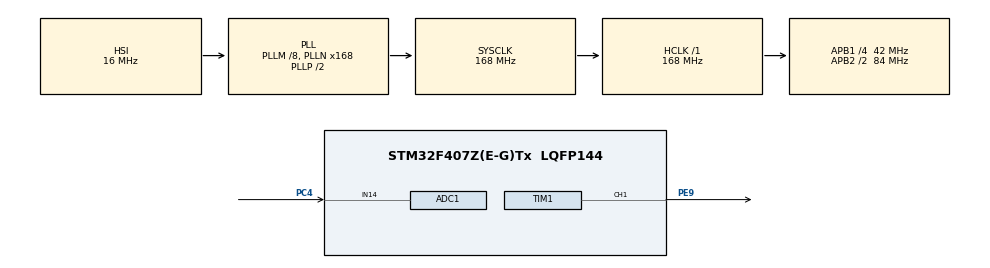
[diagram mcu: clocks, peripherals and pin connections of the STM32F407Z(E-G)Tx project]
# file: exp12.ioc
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ADC1.Channel-0\#ChannelRegularConversion=ADC_CHANNEL_14
ADC1.ContinuousConvMode=ENABLE
ADC1.DMAContinuousRequests=ENABLE
ADC1.NbrOfConversionFlag=1
ADC1.Rank-0\#ChannelRegularConversion=1
ADC1.SamplingTime-0\#ChannelRegularConversion=ADC_SAMPLETIME_3CYCLES
ADC1.master=1
Dma.ADC1.0.Direction=DMA_PERIPH_TO_MEMORY
Dma.ADC1.0.FIFOMode=DMA_FIFOMODE_DISABLE
Dma.ADC1.0.Instance=DMA2_Stream0
Dma.ADC1.0.MemDataAlignment=DMA_MDATAALIGN_HALFWORD
Dma.ADC1.0.MemInc=DMA_MINC_ENABLE
Dma.ADC1.0.Mode=DMA_CIRCULAR
Dma.ADC1.0.PeriphDataAlignment=DMA_PDATAALIGN_HALFWORD
Dma.ADC1.0.PeriphInc=DMA_PINC_DISABLE
Dma.ADC1.0.Priority=DMA_PRIORITY_LOW
Dma.Request0=ADC1
Mcu.Family=STM32F4
Mcu.Name=STM32F407Z(E-G)Tx
Mcu.Package=LQFP144
NVIC.DMA2_Stream0_IRQn=true\:0\:0\:false\:false\:true\:false\:true
NVIC.PriorityGroup=NVIC_PRIORITYGROUP_4
PC14-OSC32_IN.Mode=LSE-External-Oscillator
PC14-OSC32_IN.Signal=RCC_OSC32_IN
PC15-OSC32_OUT.Mode=LSE-External-Oscillator
PC15-OSC32_OUT.Signal=RCC_OSC32_OUT
PC4.Signal=ADCx_IN14
PE9.Signal=S_TIM1_CH1
ProjectManager.HeapSize=0x200
ProjectManager.StackSize=0x400
ProjectManager.TargetToolchain=MDK-ARM V5.27
RCC.48MHZClocksFreq_Value=84000000
RCC.AHBFreq_Value=168000000
RCC.APB1CLKDivider=RCC_HCLK_DIV4
RCC.APB1Freq_Value=42000000
RCC.APB1TimFreq_Value=84000000
RCC.APB2CLKDivider=RCC_HCLK_DIV2
RCC.APB2Freq_Value=84000000
RCC.APB2TimFreq_Value=168000000
RCC.CortexFreq_Value=168000000
RCC.HCLKFreq_Value=168000000
RCC.HSE_VALUE=25000000
RCC.HSI_VALUE=16000000
RCC.PLLM=8
RCC.PLLN=168
RCC.SYSCLKFreq_VALUE=168000000
RCC.SYSCLKSource=RCC_SYSCLKSOURCE_PLLCLK
RCC.VCOOutputFreq_Value=336000000
SH.ADCx_IN14.0=ADC1_IN14,IN14
SH.S_TIM1_CH1.0=TIM1_CH1,PWM Generation1 CH1
TIM1.AutoReloadPreload=TIM_AUTORELOAD_PRELOAD_ENABLE
TIM1.Channel-PWM\ Generation1\ CH1=TIM_CHANNEL_1
TIM1.Period=4096
VP_TIM1_VS_ClockSourceINT.Mode=Internal
board=custom

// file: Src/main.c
/* USER CODE BEGIN Header */
/**
  ******************************************************************************
  * @file           : main.c
  * @brief          : Main program body
  ******************************************************************************
  * @attention
  *
  * <h2><center>&copy; Copyright (c) 2022 STMicroelectronics.
  * All rights reserved.</center></h2>
  *
  * This software component is licensed by ST under BSD 3-Clause license,
  * the "License"; You may not use this file except in compliance with the
  * License. You may obtain a copy of the License at:
  *                        opensource.org/licenses/BSD-3-Clause
  *
  ******************************************************************************
  */
/* USER CODE END Header */

#include "main.h"

/* USER CODE BEGIN Includes */
#include "stm32_2.8_lcd.h"
#include <stdio.h>
#include <string.h>
/* USER CODE END Includes */

ADC_HandleTypeDef hadc1;
DMA_HandleTypeDef hdma_adc1;

TIM_HandleTypeDef htim1;

/* USER CODE BEGIN PV */
uint16_t ADC_ConvertedValue[128];
/* USER CODE END PV */

void SystemClock_Config(void);
static void MX_GPIO_Init(void);
static void MX_DMA_Init(void);
static void MX_TIM1_Init(void);
static void MX_ADC1_Init(void);

int main(void)
{

  /* MCU Configuration--------------------------------------------------------*/

  /* Reset of all peripherals, Initializes the Flash interface and the Systick. */
  HAL_Init();

  /* Configure the system clock */
  SystemClock_Config();

  /* Initialize all configured peripherals */
  MX_GPIO_Init();
  MX_DMA_Init();
  MX_TIM1_Init();
  MX_ADC1_Init();
  /* USER CODE BEGIN 2 */
	HAL_NVIC_ClearPendingIRQ(DMA2_Stream0_IRQn);
	STM32_LCD_Init();
	LCD_Clear(Red);
	LCD_SetBackColor(Blue);
	LCD_SetTextColor(White);
	LCD_DisplayStringLine(Line0," AD test : ");
	HAL_ADC_Start(&hadc1);

	HAL_ADC_Start_DMA(&hadc1,(uint32_t*)&ADC_ConvertedValue[0],1);
	HAL_TIM_PWM_Start(&htim1,TIM_CHANNEL_1);
  /* USER CODE END 2 */

  /* Infinite loop */
  while (1)
  {

    /* USER CODE BEGIN 3 */
		//ADC_ConvertedValue[0]= HAL_ADC_GetValue(&hadc1);
		__HAL_TIM_SetCompare(&htim1,TIM_CHANNEL_1,ADC_ConvertedValue[0]);
		LCD_Draw_NUM(35,200,ADC_ConvertedValue[0]*330/4096);
		HAL_Delay(20);
  }
  /* USER CODE END 3 */
}

void SystemClock_Config(void)
{
  RCC_OscInitTypeDef RCC_OscInitStruct = {0};
  RCC_ClkInitTypeDef RCC_ClkInitStruct = {0};

  /** Configure the main internal regulator output voltage
  */
  __HAL_RCC_PWR_CLK_ENABLE();
  __HAL_PWR_VOLTAGESCALING_CONFIG(PWR_REGULATOR_VOLTAGE_SCALE1);
  /** Initializes the CPU, AHB and APB busses clocks
  */
  RCC_OscInitStruct.OscillatorType = RCC_OSCILLATORTYPE_HSI;
  RCC_OscInitStruct.HSIState = RCC_HSI_ON;
  RCC_OscInitStruct.HSICalibrationValue = RCC_HSICALIBRATION_DEFAULT;
  RCC_OscInitStruct.PLL.PLLState = RCC_PLL_ON;
  RCC_OscInitStruct.PLL.PLLSource = RCC_PLLSOURCE_HSI;
  RCC_OscInitStruct.PLL.PLLM = 8;
  RCC_OscInitStruct.PLL.PLLN = 168;
  RCC_OscInitStruct.PLL.PLLP = RCC_PLLP_DIV2;
  RCC_OscInitStruct.PLL.PLLQ = 4;
  if (HAL_RCC_OscConfig(&RCC_OscInitStruct) != HAL_OK)
  {
    Error_Handler();
  }
  /** Initializes the CPU, AHB and APB busses clocks
  */
  RCC_ClkInitStruct.ClockType = RCC_CLOCKTYPE_HCLK|RCC_CLOCKTYPE_SYSCLK
                              |RCC_CLOCKTYPE_PCLK1|RCC_CLOCKTYPE_PCLK2;
  RCC_ClkInitStruct.SYSCLKSource = RCC_SYSCLKSOURCE_PLLCLK;
  RCC_ClkInitStruct.AHBCLKDivider = RCC_SYSCLK_DIV1;
  RCC_ClkInitStruct.APB1CLKDivider = RCC_HCLK_DIV4;
  RCC_ClkInitStruct.APB2CLKDivider = RCC_HCLK_DIV2;

  if (HAL_RCC_ClockConfig(&RCC_ClkInitStruct, FLASH_LATENCY_5) != HAL_OK)
  {
    Error_Handler();
  }
}

static void MX_ADC1_Init(void)
{

  ADC_ChannelConfTypeDef sConfig = {0};

  /** Configure the global features of the ADC (Clock, Resolution, Data Alignment and number of conversion)
  */
  hadc1.Instance = ADC1;
  hadc1.Init.ClockPrescaler = ADC_CLOCK_SYNC_PCLK_DIV4;
  hadc1.Init.Resolution = ADC_RESOLUTION_12B;
  hadc1.Init.ScanConvMode = DISABLE;
  hadc1.Init.ContinuousConvMode = ENABLE;
  hadc1.Init.DiscontinuousConvMode = DISABLE;
  hadc1.Init.ExternalTrigConvEdge = ADC_EXTERNALTRIGCONVEDGE_NONE;
  hadc1.Init.ExternalTrigConv = ADC_SOFTWARE_START;
  hadc1.Init.DataAlign = ADC_DATAALIGN_RIGHT;
  hadc1.Init.NbrOfConversion = 1;
  hadc1.Init.DMAContinuousRequests = ENABLE;
  hadc1.Init.EOCSelection = ADC_EOC_SINGLE_CONV;
  if (HAL_ADC_Init(&hadc1) != HAL_OK)
  {
    Error_Handler();
  }
  /** Configure for the selected ADC regular channel its corresponding rank in the sequencer and its sample time.
  */
  sConfig.Channel = ADC_CHANNEL_14;
  sConfig.Rank = 1;
  sConfig.SamplingTime = ADC_SAMPLETIME_3CYCLES;
  if (HAL_ADC_ConfigChannel(&hadc1, &sConfig) != HAL_OK)
  {
    Error_Handler();
  }

}

static void MX_TIM1_Init(void)
{

  TIM_ClockConfigTypeDef sClockSourceConfig = {0};
  TIM_MasterConfigTypeDef sMasterConfig = {0};
  TIM_OC_InitTypeDef sConfigOC = {0};
  TIM_BreakDeadTimeConfigTypeDef sBreakDeadTimeConfig = {0};

  htim1.Instance = TIM1;
  htim1.Init.Prescaler = 0;
  htim1.Init.CounterMode = TIM_COUNTERMODE_UP;
  htim1.Init.Period = 4096;
  htim1.Init.ClockDivision = TIM_CLOCKDIVISION_DIV1;
  htim1.Init.RepetitionCounter = 0;
  htim1.Init.AutoReloadPreload = TIM_AUTORELOAD_PRELOAD_ENABLE;
  if (HAL_TIM_Base_Init(&htim1) != HAL_OK)
  {
    Error_Handler();
  }
  sClockSourceConfig.ClockSource = TIM_CLOCKSOURCE_INTERNAL;
  if (HAL_TIM_ConfigClockSource(&htim1, &sClockSourceConfig) != HAL_OK)
  {
    Error_Handler();
  }
  if (HAL_TIM_PWM_Init(&htim1) != HAL_OK)
  {
    Error_Handler();
  }
  sMasterConfig.MasterOutputTrigger = TIM_TRGO_RESET;
  sMasterConfig.MasterSlaveMode = TIM_MASTERSLAVEMODE_DISABLE;
  if (HAL_TIMEx_MasterConfigSynchronization(&htim1, &sMasterConfig) != HAL_OK)
  {
    Error_Handler();
  }
  sConfigOC.OCMode = TIM_OCMODE_PWM1;
  sConfigOC.Pulse = 0;
  sConfigOC.OCPolarity = TIM_OCPOLARITY_HIGH;
  sConfigOC.OCNPolarity = TIM_OCNPOLARITY_HIGH;
  sConfigOC.OCFastMode = TIM_OCFAST_DISABLE;
  sConfigOC.OCIdleState = TIM_OCIDLESTATE_RESET;
  sConfigOC.OCNIdleState = TIM_OCNIDLESTATE_RESET;
  if (HAL_TIM_PWM_ConfigChannel(&htim1, &sConfigOC, TIM_CHANNEL_1) != HAL_OK)
  {
    Error_Handler();
  }
  sBreakDeadTimeConfig.OffStateRunMode = TIM_OSSR_DISABLE;
  sBreakDeadTimeConfig.OffStateIDLEMode = TIM_OSSI_DISABLE;
  sBreakDeadTimeConfig.LockLevel = TIM_LOCKLEVEL_OFF;
  sBreakDeadTimeConfig.DeadTime = 0;
  sBreakDeadTimeConfig.BreakState = TIM_BREAK_DISABLE;
  sBreakDeadTimeConfig.BreakPolarity = TIM_BREAKPOLARITY_HIGH;
  sBreakDeadTimeConfig.AutomaticOutput = TIM_AUTOMATICOUTPUT_DISABLE;
  if (HAL_TIMEx_ConfigBreakDeadTime(&htim1, &sBreakDeadTimeConfig) != HAL_OK)
  {
    Error_Handler();
  }
  HAL_TIM_MspPostInit(&htim1);

}

static void MX_DMA_Init(void)
{

  /* DMA controller clock enable */
  __HAL_RCC_DMA2_CLK_ENABLE();

  /* DMA interrupt init */
  /* DMA2_Stream0_IRQn interrupt configuration */
  HAL_NVIC_SetPriority(DMA2_Stream0_IRQn, 0, 0);
  HAL_NVIC_EnableIRQ(DMA2_Stream0_IRQn);

}

static void MX_GPIO_Init(void)
{

  /* GPIO Ports Clock Enable */
  __HAL_RCC_GPIOC_CLK_ENABLE();
  __HAL_RCC_GPIOE_CLK_ENABLE();

}

void Error_Handler(void)
{
}

/************************ (C) COPYRIGHT STMicroelectronics *****END OF FILE****/
